# SF32LB57x register map
File version: 1.0
CPU: CM33 r0p1, little endian, MPU, FPU, 3 interrupt priority bits
Registers are 32-bit, read-write, reset 0x0 unless marked. A register's access mark holds for its fields unless they carry their own. Offsets are from the block's base; [hi:lo] are bit positions.

## TSEN
Base 0x50089000
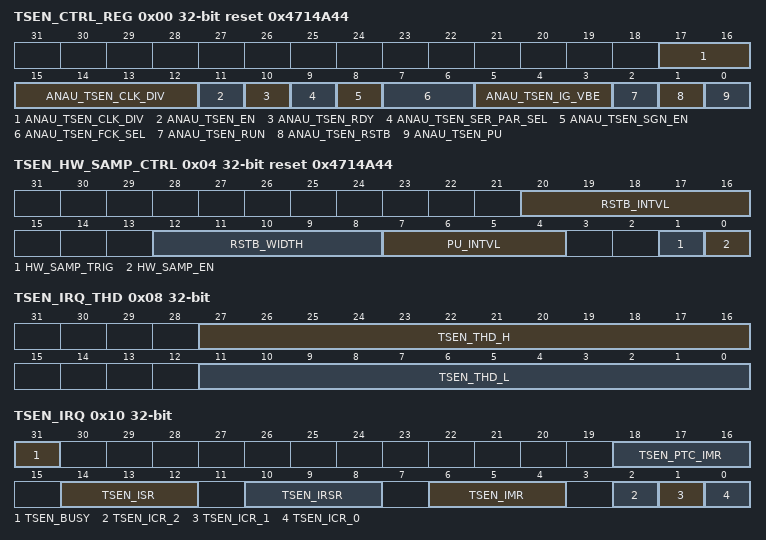
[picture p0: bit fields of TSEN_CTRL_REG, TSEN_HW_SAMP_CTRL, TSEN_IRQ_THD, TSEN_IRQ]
0x00 TSEN_CTRL_REG reset 0x4714A44 — TSEN Analog Control Register
  [17:12] ANAU_TSEN_CLK_DIV — gen tsen clk by divide pclk_peri by anau_tsen_clk_div
  [11] ANAU_TSEN_EN — enable clk output from digital ctrl while sw mode
  [10] ANAU_TSEN_RDY — tsen ready
  [9] ANAU_TSEN_SER_PAR_SEL — serial-parallel output selection
  [8] ANAU_TSEN_SGN_EN — signature-mode enable
  [7:6] ANAU_TSEN_FCK_SEL — select internal clock frequency
  [5:3] ANAU_TSEN_IG_VBE — bias current selection to tune vba
  [2] ANAU_TSEN_RUN — enable tsen run
  [1] ANAU_TSEN_RSTB — resetb for tsen
  [0] ANAU_TSEN_PU — power up tsen
0x04 TSEN_HW_SAMP_CTRL reset 0x4714A44 — TSEN HW_SAMP Control Register
  [20:16] RSTB_INTVL — time between rstb posedge and run posedge, base unit 2.67us
  [12:8] RSTB_WIDTH — rstb pulse width, base unit 2.67us
  [7:4] PU_INTVL — time between pu posedge and rstb negedge, base unit 2.67us
  [1] HW_SAMP_TRIG
  [0] HW_SAMP_EN
0x08 TSEN_IRQ_THD — Tsen Read Data
  [27:16] TSEN_THD_H, [11:0] TSEN_THD_L
0x0C TSEN_RDATA — Tsen Read Data
  [11:0] TSEN_RDATA
0x10 TSEN_IRQ
  [31] TSEN_BUSY
  [18:16] TSEN_PTC_IMR — bit0: tsen done irq; bit1: down cross irq; bit2: up cross irq
  [14:12] TSEN_ISR — bit0: tsen done irq; bit1: down cross irq; bit2: up cross irq
  [10:8] TSEN_IRSR — bit0: tsen done irq; bit1: down cross irq; bit2: up cross irq
  [6:4] TSEN_IMR — bit0: tsen done irq; bit1: down cross irq; bit2: up cross irq
  [2] TSEN_ICR_2 — up cross irq clear
  [1] TSEN_ICR_1 — down cross irq clear
  [0] TSEN_ICR_0 — tsen done irq clear

## WDT1
Base 0x50094000
Same registers: WDT2 0x40041000, IWDT 0x500CC000
0x00 WDT_CVR0 — WatchDog Counter Value 0
  [23:0] COUNT_VALUE_0 — Count Value for 1st TimeOut
0x04 WDT_CVR1 — WatchDog Counter Value 1
  [23:0] COUNT_VALUE_1 — Count Value for 2nd TimeOut
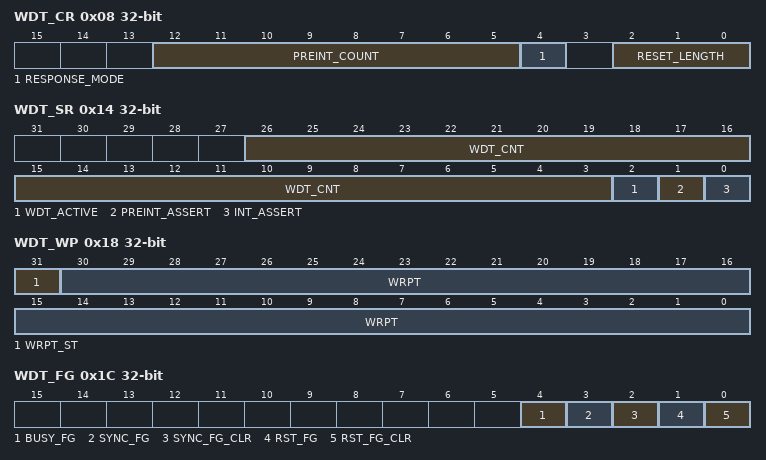
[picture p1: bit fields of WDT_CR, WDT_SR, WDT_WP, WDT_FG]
0x08 WDT_CR — WatchDog Control Register
  [12:5] PREINT_COUNT — Count Value for pre int
  [4] RESPONSE_MODE — 0:reset only, 1:interrupt and reset
  [2:0] RESET_LENGTH — reset pulse length in number of wdt clock cycles
0x0C WDT_CCR — WatchDog Counter Control Register
  [7:0] COUNTER_CONTROL — SinglePulse /Write 8'h76 to restart, write8'h34 to stop, else do nothing
0x10 WDT_ICR — WatchDog Interrupt Clear Register
  [0] INT_CLR — SinglePulse /A pulse to clear interrupt
0x14 WDT_SR — WatchDog Status Register
  [26:3] WDT_CNT
  [2] WDT_ACTIVE — Watchdog runs when 1, else 0
  [1] PREINT_ASSERT — pre Interrupt assert when 1
  [0] INT_ASSERT — Interrupt assert when 1
0x18 WDT_WP — WatchDog Write Protect Register
  [31] WRPT_ST
  [30:0] WRPT — write 0x58ab99fc generate write_protect, write 0x51ff8621 to release
0x1C WDT_FG — WatchDog Flag Register
  [4] BUSY_FG, [3] SYNC_FG, [2] SYNC_FG_CLR, [1] RST_FG, [0] RST_FG_CLR

## PDM1
Base 0x5009A000
Same registers: PDM2 0x5009B000
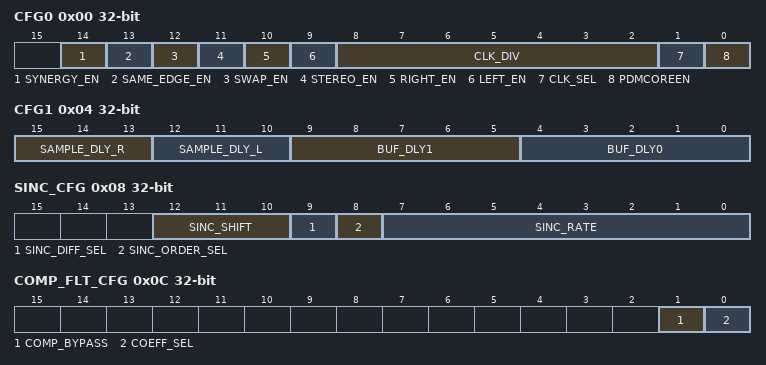
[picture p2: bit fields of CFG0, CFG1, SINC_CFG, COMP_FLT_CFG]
0x00 CFG0
  [14] SYNERGY_EN
  [13] SAME_EDGE_EN
  [12] SWAP_EN — 1: Swap right channel and left channel; 0: Not swap
  [11] STEREO_EN — 1:Enable double channels; 0: Disable double channels
  [10] RIGHT_EN — 1: Enable right channel; 0: Disable right channel
  [9] LEFT_EN — 1: Enable left channel; 0: Disable left channel
  [8:2] CLK_DIV — Clock frequency division ratio
  [1] CLK_SEL — 1:Clk select audio pll; 0: Clk selct xtal 9.6MHz
  [0] PDMCOREEN — 1:Enable pdm 2 pcm module; 0: Disable pdm 2 pcm module
0x04 CFG1
  [15:13] SAMPLE_DLY_R — The number of delay d_ff before the right data stream in processing
  [12:10] SAMPLE_DLY_L — The number of delay d_ff before the left data stream in processing
  [9:5] BUF_DLY1 — The number of delay cell before the data stream sampled
  [4:0] BUF_DLY0 — The number of delay cell before the data stream sampled
0x08 SINC_CFG
  [12:10] SINC_SHIFT, [9] SINC_DIFF_SEL, [8] SINC_ORDER_SEL, [7:0] SINC_RATE
0x0C COMP_FLT_CFG
  [1] COMP_BYPASS, [0] COEFF_SEL
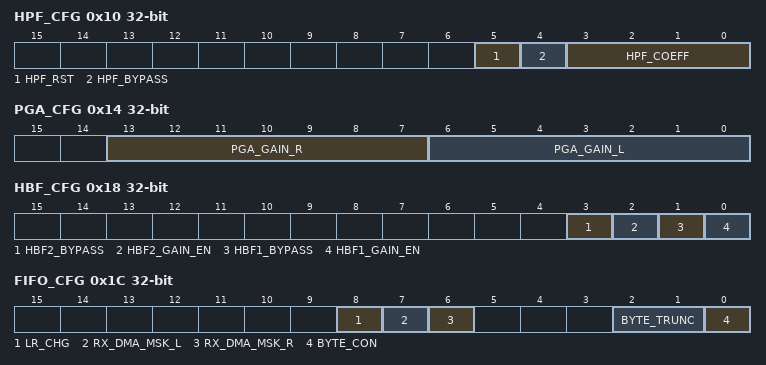
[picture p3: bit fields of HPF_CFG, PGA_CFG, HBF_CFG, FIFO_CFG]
0x10 HPF_CFG
  [5] HPF_RST, [4] HPF_BYPASS, [3:0] HPF_COEFF
0x14 PGA_CFG
  [13:7] PGA_GAIN_R, [6:0] PGA_GAIN_L
0x18 HBF_CFG
  [3] HBF2_BYPASS, [2] HBF2_GAIN_EN, [1] HBF1_BYPASS, [0] HBF1_GAIN_EN
0x1C FIFO_CFG
  [8] LR_CHG
  [7] RX_DMA_MSK_L
  [6] RX_DMA_MSK_R
  [2:1] BYTE_TRUNC — 1: trunc 24bits to 16bit ; 0: maintain 24bits ;2: 8bits ; 3: 32bits
  [0] BYTE_CON — 1: combine left channel and right channel; 0: not combine left channel and right channel
0x20 DATA_L
  [31:0] DMA_ENTRY_L
0x24 DATA_R
  [31:0] DMA_ENTRY_R
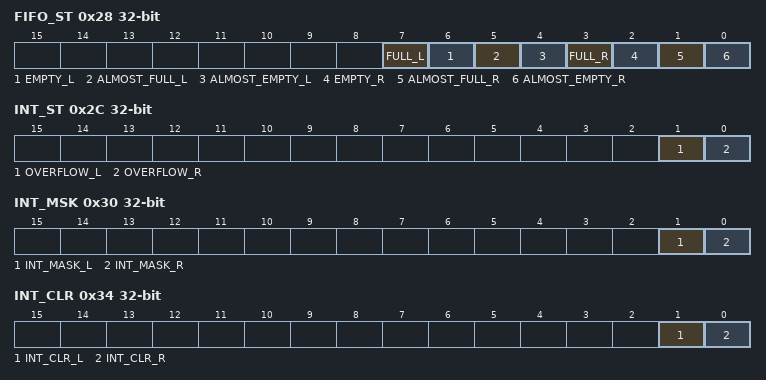
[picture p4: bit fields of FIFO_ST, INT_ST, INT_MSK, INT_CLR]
0x28 FIFO_ST
  [7] FULL_L, [6] EMPTY_L, [5] ALMOST_FULL_L, [4] ALMOST_EMPTY_L, [3] FULL_R, [2] EMPTY_R, [1] ALMOST_FULL_R, [0] ALMOST_EMPTY_R
0x2C INT_ST
  [1] OVERFLOW_L, [0] OVERFLOW_R
0x30 INT_MSK
  [1] INT_MASK_L, [0] INT_MASK_R
0x34 INT_CLR
  [1] INT_CLR_L, [0] INT_CLR_R
